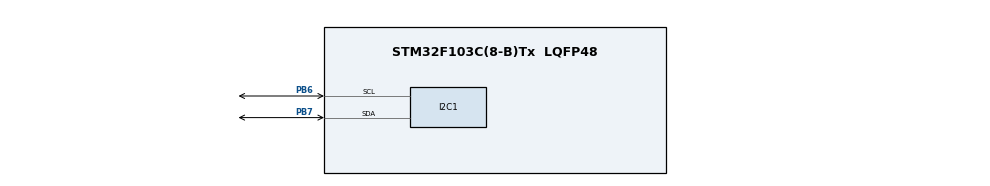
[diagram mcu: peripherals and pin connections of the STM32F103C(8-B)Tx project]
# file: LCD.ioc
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Mcu.Family=STM32F1
Mcu.Name=STM32F103C(8-B)Tx
Mcu.Package=LQFP48
NVIC.PriorityGroup=NVIC_PRIORITYGROUP_4
PA13.Mode=Serial_Wire
PA13.Signal=SYS_JTMS-SWDIO
PA14.Mode=Serial_Wire
PA14.Signal=SYS_JTCK-SWCLK
PB6.Mode=I2C
PB6.Signal=I2C1_SCL
PB7.Mode=I2C
PB7.Signal=I2C1_SDA
ProjectManager.HeapSize=0x200
ProjectManager.StackSize=0x400
ProjectManager.TargetToolchain=MDK-ARM V5.27
RCC.APB1Freq_Value=8000000
RCC.APB2Freq_Value=8000000
board=custom

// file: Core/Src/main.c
/* USER CODE BEGIN Header */
/**
  ******************************************************************************
  * @file           : main.c
  * @brief          : Main program body
  ******************************************************************************
  * @attention
  *
  * <h2><center>&copy; Copyright (c) 2020 STMicroelectronics.
  * All rights reserved.</center></h2>
  *
  * This software component is licensed by ST under BSD 3-Clause license,
  * the "License"; You may not use this file except in compliance with the
  * License. You may obtain a copy of the License at:
  *                        opensource.org/licenses/BSD-3-Clause
  *
  ******************************************************************************
  */
/* USER CODE END Header */

#include "main.h"
/* USER CODE BEGIN Includes */
#include "i2c-lcd.h"
#include "ds1307.h"
#include "stdio.h"
/* USER CODE END Includes */

I2C_HandleTypeDef hi2c1;

/* USER CODE BEGIN PV */
DS1307_Handle ds1307;
DS1307_TIME time;
I2C_HandleTypeDef i2c_handle;
/* USER CODE END PV */

void SystemClock_Config(void);
static void MX_GPIO_Init(void);
static void MX_I2C1_Init(void);

/* USER CODE BEGIN 0 */
DS1307_RESULT confDS1307(void) {

ds1307.i2c = &i2c_handle;
 ds1307.DS1307_ADDRESS = 0xD0;
 ds1307.DS1307_CLOCK = 100000;
 ds1307.DS1307_I2Cx = I2C1;
 ds1307.TIMEOUT = 1000;
 DS1307_RESULT res;
 res = DS1307_Init(&ds1307);
 if (res != DS1307_RES_OK) {
 return DS1307_RES_ERROR;
 }
 res = DS1307_ClockResume(&ds1307);
 if (res != DS1307_RES_OK) {
 return DS1307_RES_ERROR;
 }
 res = DS1307_EnableSquareWave(&ds1307);
 if (res != DS1307_RES_OK) {
 return DS1307_RES_ERROR;
 }
 res = DS1307_SelectRate(&ds1307, DS1307_RATE_1HZ);
 if (res != DS1307_RES_OK) {
 return DS1307_RES_ERROR;
 }
 return DS1307_RES_OK;
}

		char Now[20];//gio phut
int gio=0,phut=0,giay=0;
/* USER CODE END 0 */

int main(void)
{

  /* MCU Configuration--------------------------------------------------------*/

  /* Reset of all peripherals, Initializes the Flash interface and the Systick. */
  HAL_Init();

  /* Configure the system clock */
  SystemClock_Config();

  /* Initialize all configured peripherals */
  MX_GPIO_Init();
  MX_I2C1_Init();
	lcd_init();

lcd_clear_display();
	HAL_Delay(50);
	lcd_goto_XY(1,0);
	lcd_send_string("UTE");
	lcd_goto_XY(2,1);
	lcd_send_string("KTMT-THINH");
	HAL_Delay(500);
	//HAL_GPIO_WritePin(GPIOC,13,1);
  /* USER CODE BEGIN 2 */
	if (confDS1307()!=DS1307_RES_OK)
		{
			}
time.hour=gio;
		time.minute=phut;
		time.second=giay;
			DS1307_SetTime(&ds1307,time);
			lcd_clear_display();
			HAL_Delay(50);
  /* USER CODE END 2 */

  /* Infinite loop */
  while (1)
  {

    /* USER CODE BEGIN 3 */

		time=DS1307_GetTime(&ds1307);
			sprintf(Now,"%0.2d:%0.2d:%0.2d ",time.hour,time.minute,time.second);
		lcd_goto_XY(1,0);
		lcd_send_string(Now);
  }
  /* USER CODE END 3 */
}

void SystemClock_Config(void)
{
  RCC_OscInitTypeDef RCC_OscInitStruct = {0};
  RCC_ClkInitTypeDef RCC_ClkInitStruct = {0};

  /** Initializes the CPU, AHB and APB busses clocks
  */
  RCC_OscInitStruct.OscillatorType = RCC_OSCILLATORTYPE_HSI;
  RCC_OscInitStruct.HSIState = RCC_HSI_ON;
  RCC_OscInitStruct.HSICalibrationValue = RCC_HSICALIBRATION_DEFAULT;
  RCC_OscInitStruct.PLL.PLLState = RCC_PLL_NONE;
  if (HAL_RCC_OscConfig(&RCC_OscInitStruct) != HAL_OK)
  {
    Error_Handler();
  }
  /** Initializes the CPU, AHB and APB busses clocks
  */
  RCC_ClkInitStruct.ClockType = RCC_CLOCKTYPE_HCLK|RCC_CLOCKTYPE_SYSCLK
                              |RCC_CLOCKTYPE_PCLK1|RCC_CLOCKTYPE_PCLK2;
  RCC_ClkInitStruct.SYSCLKSource = RCC_SYSCLKSOURCE_HSI;
  RCC_ClkInitStruct.AHBCLKDivider = RCC_SYSCLK_DIV1;
  RCC_ClkInitStruct.APB1CLKDivider = RCC_HCLK_DIV1;
  RCC_ClkInitStruct.APB2CLKDivider = RCC_HCLK_DIV1;

  if (HAL_RCC_ClockConfig(&RCC_ClkInitStruct, FLASH_LATENCY_0) != HAL_OK)
  {
    Error_Handler();
  }
}

static void MX_I2C1_Init(void)
{

  hi2c1.Instance = I2C1;
  hi2c1.Init.ClockSpeed = 100000;
  hi2c1.Init.DutyCycle = I2C_DUTYCYCLE_2;
  hi2c1.Init.OwnAddress1 = 0;
  hi2c1.Init.AddressingMode = I2C_ADDRESSINGMODE_7BIT;
  hi2c1.Init.DualAddressMode = I2C_DUALADDRESS_DISABLE;
  hi2c1.Init.OwnAddress2 = 0;
  hi2c1.Init.GeneralCallMode = I2C_GENERALCALL_DISABLE;
  hi2c1.Init.NoStretchMode = I2C_NOSTRETCH_DISABLE;
  if (HAL_I2C_Init(&hi2c1) != HAL_OK)
  {
    Error_Handler();
  }

}

static void MX_GPIO_Init(void)
{

  /* GPIO Ports Clock Enable */
  __HAL_RCC_GPIOA_CLK_ENABLE();
  __HAL_RCC_GPIOB_CLK_ENABLE();

}

void Error_Handler(void)
{
}

/************************ (C) COPYRIGHT STMicroelectronics *****END OF FILE****/
